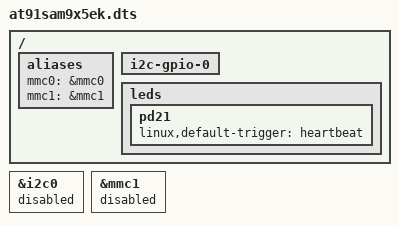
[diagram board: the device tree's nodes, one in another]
/dts-v1/;

#include <dt-bindings/gpio/gpio.h>
#include <dt-bindings/pinctrl/at91.h>

#include <arm/at91sam9x5.dtsi>
#include <arm/at91sam9x5_lcd.dtsi>
#include <arm/at91sam9x5dm.dtsi>
#include <arm/at91sam9x5ek.dtsi>

/ {
	aliases {
		mmc0 = &mmc0;
		mmc1 = &mmc1;
	};

	i2c-gpio-0 {
		status = "okay";
	};

	leds {
		/*
		 * PB18 has a resource conflict since it is both used
                 * as a heartbeat LED and 1-wire bus in the kernel
                 * device tree. Since 1-wire EEPROMs contains
                 * importatnt revision information as a part of
                 * Barebox DT stup we move heartbeat to PD21 and
                 * remove the original pb18 node
		 */

		/delete-node/ pb18;

		pd21 {
			linux,default-trigger = "heartbeat";
		};
	};
};

&i2c0 {
	status = "disabled";
};

/*
 * This one conflicts with SPI NOR on the SoM
 */
&mmc1 {
	status = "disabled";
};
